AUTOSAR XML (schema 4-0-3)
package /ComponentTypes
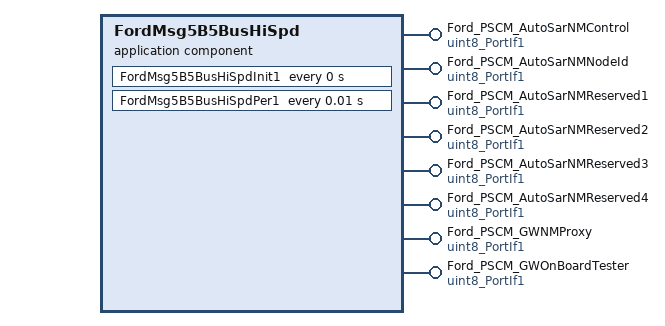
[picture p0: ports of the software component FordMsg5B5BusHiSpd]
  application sw component type FordMsg5B5BusHiSpd
    8 x provide port, all with provided-interface=uint8_PortIf1:
      Ford_PSCM_AutoSarNMControl: nonqueued-sender-com-spec{data-element=Val, init-value=0}  # Ford Power Steering Control Module AUTOSAR NM Control
      Ford_PSCM_AutoSarNMNodeId: nonqueued-sender-com-spec{data-element=Val, init-value=181}  # Ford Power Steering Control Module AUTOSAR NM Node Identification
      Ford_PSCM_AutoSarNMReserved1: nonqueued-sender-com-spec{data-element=Val, init-value=255}  # It provide Power Steering Control Module AUTOSAR NM Reserved 1 to CAN. Doc Unit: Ford_PSCM_AutoSarNMReserved1.
      Ford_PSCM_AutoSarNMReserved2: nonqueued-sender-com-spec{data-element=Val, init-value=255}  # It provide Power Steering Control Module AUTOSAR NM Reserved 2 to CAN.Doc Unit: Ford_PSCM_AutoSarNMReserved2.
      Ford_PSCM_AutoSarNMReserved3: nonqueued-sender-com-spec{data-element=Val, init-value=255}  # It Provide Power Steering Control Module AUTOSAR NM Reserved 3 to CAN. Doc Unit: Ford_PSCM_AutoSarNMReserved3
      Ford_PSCM_AutoSarNMReserved4: nonqueued-sender-com-spec{data-element=Val, init-value=255}  # It provide Power Steering Control Module AUTOSAR NM Reserved 4 to CAN.Doc Unit: Ford_PSCM_AutoSarNMReserved4.
      Ford_PSCM_GWNMProxy: nonqueued-sender-com-spec{data-element=Val, init-value=255}  # It Provide Power Steering Control Module Gateway NM Proxy to CAN.Doc Unit: Ford_PSCM_GWNMProxy
      Ford_PSCM_GWOnBoardTester: nonqueued-sender-com-spec{data-element=Val, init-value=255}  # It provide Power Steering Control Module Gateway On Board Tester to CAN. Doc Unit: Ford_PSCM_GWOnBoardTester.
    behavior FordMsg5B5BusHiSpd_InternalBehavior
      ar-typed-per-instance-memorys:
        8 x data, all with sw-calibration-access=READ-ONLY, type=uint8:
          PwrSteerCtrlModlArNmCtrlPrev
          PwrSteerCtrlModlArNmNodIdnPrev
          PwrSteerCtrlModlArNmResd{1..4}Prev
          PwrSteerCtrlModlGatewyNmOnBdTestPrev
          PwrSteerCtrlModlGatewyNmProxyPrev
      timing event FordMsg5B5BusHiSpd_InitEvent: start-on-event=FordMsg5B5BusHiSpdInit1, period=0
      timing event TMT_FordMsg5B5BusHiSpdPer1: start-on-event=FordMsg5B5BusHiSpdPer1, period=0.01
      runnable FordMsg5B5BusHiSpdInit1
      runnable FordMsg5B5BusHiSpdPer1
        data-send-points:
          8 x access:
            SEND_PSCM_AutoSarNMControl_Val: accessed-variable=Ford_PSCM_AutoSarNMControl.Val
            SEND_PSCM_AutoSarNMNodeId_Val: accessed-variable=Ford_PSCM_AutoSarNMNodeId.Val
            SEND_PSCM_AutoSarNMReserved{1..4}_Val: accessed-variable=Ford_PSCM_AutoSarNMReserved{1..4}.Val
            SEND_PSCM_GWNMProxy_Val: accessed-variable=Ford_PSCM_GWNMProxy.Val
            SEND_PSCM_GWOnBoardTester_Val: accessed-variable=Ford_PSCM_GWOnBoardTester.Val
  swc implementation FordMsg5B5BusHiSpd_Implementation: behavior=FordMsg5B5BusHiSpd_InternalBehavior
    code-descriptors:
      code Default: artifact-descriptors=autosar-engineering-object={short-label=Default, category=SWSRC}
